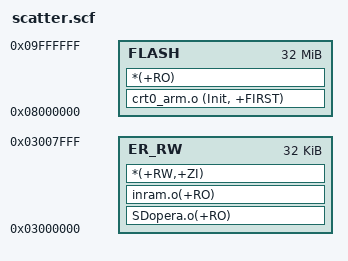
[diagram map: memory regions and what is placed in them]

FLASH 0x08000000 0x2000000; The first load region is at 0x08000000.
{
	FLASH 0x08000000 0x2000000
	{
		crt0_arm.o (Init, +FIRST)
		*(+RO)
	}
	ER_RW 0x03000000 0x8000 ;The address is 0x03000000.
	{
		SDopera.o(+RO)
		inram.o(+RO)
		*(+RW,+ZI) ;
	}
}
